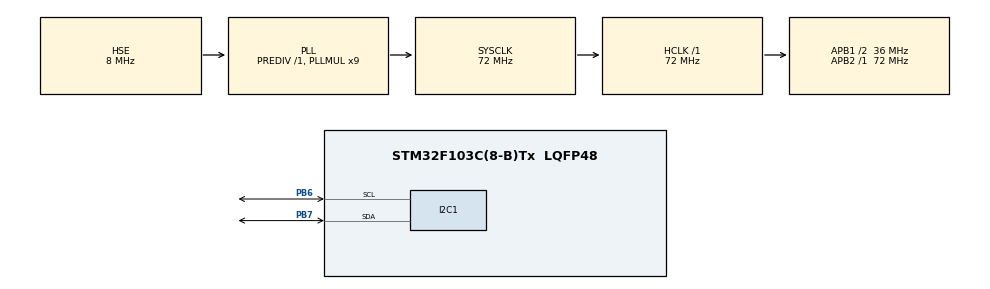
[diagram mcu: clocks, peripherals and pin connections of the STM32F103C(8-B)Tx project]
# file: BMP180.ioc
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Mcu.Family=STM32F1
RCC.PLLSourceVirtual=RCC_PLLSOURCE_HSE
PD1-OSC_OUT.Mode=HSE-External-Oscillator
NVIC.I2C1_EV_IRQn=true\:0\:0\:false\:false\:true\:true\:true
PD0-OSC_IN.Signal=RCC_OSC_IN
RCC.APB1CLKDivider=RCC_HCLK_DIV2
RCC.SYSCLKSource=RCC_SYSCLKSOURCE_PLLCLK
ProjectManager.StackSize=0x400
PD1-OSC_OUT.Signal=RCC_OSC_OUT
PA13.Signal=SYS_JTMS-SWDIO
ProjectManager.TargetToolchain=STM32CubeIDE
I2C1.I2C_Mode=I2C_Fast
RCC.HCLKFreq_Value=72000000
RCC.APB2TimFreq_Value=72000000
PB6.Signal=I2C1_SCL
PB6.Mode=I2C
RCC.USBFreq_Value=72000000
RCC.AHBFreq_Value=72000000
PD0-OSC_IN.Mode=HSE-External-Oscillator
PB3.Mode=Trace_Asynchronous_SW
board=custom
RCC.PLLMUL=RCC_PLL_MUL9
RCC.APB2Freq_Value=72000000
PA14.Mode=Trace_Asynchronous_SW
PB7.Signal=I2C1_SDA
PA13.Mode=Trace_Asynchronous_SW
NVIC.I2C1_ER_IRQn=true\:0\:0\:false\:false\:true\:true\:true
Mcu.Name=STM32F103C(8-B)Tx
PB3.Signal=SYS_JTDO-TRACESWO
RCC.SYSCLKFreq_VALUE=72000000
Mcu.Package=LQFP48
PB7.Mode=I2C
PA14.Signal=SYS_JTCK-SWCLK
ProjectManager.HeapSize=0x200
NVIC.PriorityGroup=NVIC_PRIORITYGROUP_4
RCC.APB1TimFreq_Value=72000000
RCC.APB1Freq_Value=36000000

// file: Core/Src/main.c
/* USER CODE BEGIN Header */
/**
  ******************************************************************************
  * @file           : main.c
  * @brief          : Main program body
  * author			: Baki ALMACI
  ******************************************************************************
  Description
	BMP180 Datasheet can be found here, https://cdn-shop.adafruit.com/datasheets/BST-BMP180-DS000-09.pdf
	This project was written considering the data sheet.
  ******************************************************************************
  **/
/* USER CODE END Header */
#include "main.h"

/* USER CODE BEGIN Includes */
#include <math.h>
#include "stdio.h"
/* USER CODE END Includes */

/* USER CODE BEGIN PTD */
void InitBMP(void);
uint16_t Get_UTemp (void);
float BMP180_GetTemp (void);
uint32_t Get_UPress (int oss);
float BMP180_GetPress (int oss);
float BMP180_GetAlt (int oss);
/* USER CODE END PTD */

/* USER CODE BEGIN PD */
#define BMP180_I2C &hi2c1
#define BMP180_ADDRESS 0xEE
#define atmPress 101325 //Pa
/* USER CODE END PD */

I2C_HandleTypeDef hi2c1;

/* USER CODE BEGIN PV */
short AC1 = 0;
short AC2 = 0;
short AC3 = 0;
unsigned short AC4 = 0;
unsigned short AC5 = 0;
unsigned short AC6 = 0;
short B1 = 0;
short B2 = 0;
short MB = 0;
short MC = 0;
short MD = 0;
long UT = 0;
short oss = 0;
long UP = 0;
long X1 = 0;
long X2 = 0;
long X3 = 0;
long B3 = 0;
long B5 = 0;
unsigned long B4 = 0;
long B6 = 0;
unsigned long B7 = 0;
long Press = 0;
long Temp = 0;
float Temperature = 0;
float Pressure = 0;
float Altitude = 0;
/* USER CODE END PV */

void SystemClock_Config(void);
static void MX_GPIO_Init(void);
static void MX_I2C1_Init(void);

int main(void)
{

  /* MCU Configuration--------------------------------------------------------*/

  /* Reset of all peripherals, Initializes the Flash interface and the Systick. */
  HAL_Init();

  /* Configure the system clock */
  SystemClock_Config();

  /* Initialize all configured peripherals */
  MX_GPIO_Init();
  MX_I2C1_Init();
  /* USER CODE BEGIN 2 */
  InitBMP();
  /* USER CODE END 2 */

  /* Infinite loop */
  while (1)
  {

    /* USER CODE BEGIN 3 */
	  Temperature = BMP180_GetTemp();
	  Pressure = BMP180_GetPress(0);
	  Altitude = BMP180_GetAlt(0);
  }
  /* USER CODE END 3 */
}

void SystemClock_Config(void)
{
  RCC_OscInitTypeDef RCC_OscInitStruct = {0};
  RCC_ClkInitTypeDef RCC_ClkInitStruct = {0};

  /** Initializes the RCC Oscillators according to the specified parameters
  * in the RCC_OscInitTypeDef structure.
  */
  RCC_OscInitStruct.OscillatorType = RCC_OSCILLATORTYPE_HSE;
  RCC_OscInitStruct.HSEState = RCC_HSE_ON;
  RCC_OscInitStruct.HSEPredivValue = RCC_HSE_PREDIV_DIV1;
  RCC_OscInitStruct.HSIState = RCC_HSI_ON;
  RCC_OscInitStruct.PLL.PLLState = RCC_PLL_ON;
  RCC_OscInitStruct.PLL.PLLSource = RCC_PLLSOURCE_HSE;
  RCC_OscInitStruct.PLL.PLLMUL = RCC_PLL_MUL9;
  if (HAL_RCC_OscConfig(&RCC_OscInitStruct) != HAL_OK)
  {
    Error_Handler();
  }
  /** Initializes the CPU, AHB and APB buses clocks
  */
  RCC_ClkInitStruct.ClockType = RCC_CLOCKTYPE_HCLK|RCC_CLOCKTYPE_SYSCLK
                              |RCC_CLOCKTYPE_PCLK1|RCC_CLOCKTYPE_PCLK2;
  RCC_ClkInitStruct.SYSCLKSource = RCC_SYSCLKSOURCE_PLLCLK;
  RCC_ClkInitStruct.AHBCLKDivider = RCC_SYSCLK_DIV1;
  RCC_ClkInitStruct.APB1CLKDivider = RCC_HCLK_DIV2;
  RCC_ClkInitStruct.APB2CLKDivider = RCC_HCLK_DIV1;

  if (HAL_RCC_ClockConfig(&RCC_ClkInitStruct, FLASH_LATENCY_2) != HAL_OK)
  {
    Error_Handler();
  }
}

static void MX_I2C1_Init(void)
{

  hi2c1.Instance = I2C1;
  hi2c1.Init.ClockSpeed = 400000;
  hi2c1.Init.DutyCycle = I2C_DUTYCYCLE_2;
  hi2c1.Init.OwnAddress1 = 0;
  hi2c1.Init.AddressingMode = I2C_ADDRESSINGMODE_7BIT;
  hi2c1.Init.DualAddressMode = I2C_DUALADDRESS_DISABLE;
  hi2c1.Init.OwnAddress2 = 0;
  hi2c1.Init.GeneralCallMode = I2C_GENERALCALL_DISABLE;
  hi2c1.Init.NoStretchMode = I2C_NOSTRETCH_DISABLE;
  if (HAL_I2C_Init(&hi2c1) != HAL_OK)
  {
    Error_Handler();
  }

}

static void MX_GPIO_Init(void)
{

  /* GPIO Ports Clock Enable */
  __HAL_RCC_GPIOD_CLK_ENABLE();
  __HAL_RCC_GPIOA_CLK_ENABLE();
  __HAL_RCC_GPIOB_CLK_ENABLE();

}

/* USER CODE BEGIN 4 */
void InitBMP(void){
	uint8_t Callib_Data[22] = {0};
	uint16_t Callib_Start = 0xAA;
	HAL_I2C_Mem_Read(BMP180_I2C, BMP180_ADDRESS, Callib_Start, 1, Callib_Data,22, HAL_MAX_DELAY);

	AC1 = ((Callib_Data[0] << 8) | Callib_Data[1]);
	AC2 = ((Callib_Data[2] << 8) | Callib_Data[3]);
	AC3 = ((Callib_Data[4] << 8) | Callib_Data[5]);
	AC4 = ((Callib_Data[6] << 8) | Callib_Data[7]);
	AC5 = ((Callib_Data[8] << 8) | Callib_Data[9]);
	AC6 = ((Callib_Data[10] << 8) | Callib_Data[11]);
	B1 = ((Callib_Data[12] << 8) | Callib_Data[13]);
	B2 = ((Callib_Data[14] << 8) | Callib_Data[15]);
	MB = ((Callib_Data[16] << 8) | Callib_Data[17]);
	MC = ((Callib_Data[18] << 8) | Callib_Data[19]);
	MD = ((Callib_Data[20] << 8) | Callib_Data[21]);
}

uint16_t Get_UTemp (void)
{
	uint8_t datatowrite = 0x2E;
	uint8_t Temp_RAW[2] = {0};
	HAL_I2C_Mem_Write(BMP180_I2C, BMP180_ADDRESS, 0xF4, 1, &datatowrite, 1, 1000);
	HAL_Delay (5);  // wait 4.5 ms
	HAL_I2C_Mem_Read(BMP180_I2C, BMP180_ADDRESS, 0xF6, 1, Temp_RAW, 2, 1000);
	return ((Temp_RAW[0]<<8) + Temp_RAW[1]);
}

float BMP180_GetTemp (void)
{
	UT = Get_UTemp();
	X1 = ((UT-AC6) * (AC5/(pow(2,15))));
	X2 = ((MC*(pow(2,11))) / (X1+MD));
	B5 = X1+X2;
	Temp = (B5+8)/(pow(2,4));
	return Temp/10.0;
}

uint32_t Get_UPress (int oss)   // over sampling settings 0,1,2,3
{
	uint8_t datatowrite = 0x34+(oss<<6);
	uint8_t Press_RAW[3] = {0};
	HAL_I2C_Mem_Write(BMP180_I2C, BMP180_ADDRESS, 0xF4, 1, &datatowrite, 1, 1000);
	switch (oss)
	{
		case (0):
			HAL_Delay (5);
			break;
		case (1):
			HAL_Delay (8);
			break;
		case (2):
			HAL_Delay (14);
			break;
		case (3):
			HAL_Delay (26);
			break;
	}
	HAL_I2C_Mem_Read(BMP180_I2C, BMP180_ADDRESS, 0xF6, 1, Press_RAW, 3, 1000);
	return (((Press_RAW[0]<<16)+(Press_RAW[1]<<8)+Press_RAW[2]) >> (8-oss));
}

float BMP180_GetPress (int oss)
{
	UP = Get_UPress(oss);

	B6 = B5 - 4000;

	X1 = (B2*(B6*B6/pow(2,12)))/pow(2,11);
	X2 = AC2 * B6 / pow(2,11);
	X3 = X1 + X2;

	B3 = (((AC1*4+X3) << oss) + 2) / 4;

	X1 = AC3 * B6 / pow(2,13);
	X2 = (B1 * (B6 * B6 / pow(2,12))) / pow(2,16);
	X3 = ((X1+X2)+2) / pow(2,2);

	B4 = AC4 * (unsigned long)(X3 + 32768) / pow(2,15);
	B7 = ((unsigned long)UP - B3)* (50000 >> oss);

	if(B7 < 0x80000000)
		Press = (B7 * 2) / B4;
	else
		Press = (B7 / B4) * 2;

	X1 = (Press / pow(2,8)) * (Press / pow(2,8));
	X1 = (X1 * 3038) / pow (2,16);
	X2 = (-7357 * Press) / pow(2,16);

	Press = Press + (X1 + X2 + 3791) / pow(2,4);

	return Press;
}

float BMP180_GetAlt (int oss)
{
	BMP180_GetPress (oss);
	return 44330*(1-(pow((Press/(float)atmPress), 0.19029495718)));
}
/* USER CODE END 4 */

void Error_Handler(void)
{
  __disable_irq();
  while (1)
  {
  }
}

/************************ (C) COPYRIGHT STMicroelectronics *****END OF FILE****/
